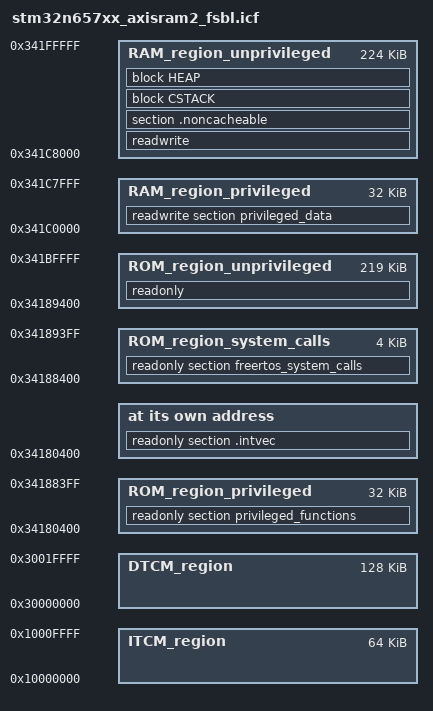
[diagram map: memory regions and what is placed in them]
/*###ICF### Section handled by ICF editor, don't touch! ****/
/*-Editor annotation file-*/
/* IcfEditorFile="$TOOLKIT_DIR$\config\ide\IcfEditor\cortex_v1_0.xml" */
/*-Specials-*/
define symbol __ICFEDIT_intvec_start__ = 0x34180400;
/*-Memory Regions-*/
define symbol __ICFEDIT_region_ROM_start__ = 0x34180400;
define symbol __ICFEDIT_region_ROM_end__   = 0x341BFFFF;
define symbol __ICFEDIT_region_RAM_start__ = 0x341C0000;
define symbol __ICFEDIT_region_RAM_end__   = 0x341FFFFF;
/*-Sizes-*/
define symbol __ICFEDIT_size_cstack__ = 0x800;
define symbol __ICFEDIT_size_heap__   = 0x200;
/**** End of ICF editor section. ###ICF###*/

define symbol __region_ITCM_start__  = 0x10000000;
define symbol __region_ITCM_end__    = 0x1000FFFF;
define symbol __region_DTCM_start__  = 0x30000000;
define symbol __region_DTCM_end__    = 0x3001FFFF;


/* Flash Organization
 *  1. Privileged Code:
 *      Start   : 0x34180400
 *      End     : 0x341883FF
 *      Size    : 32 Kbytes
 *  2. System calls:
 *      Start   : 0x34188400
 *      End     : 0x341893FF
 *      Size    : 4 Kbytes
 *  3. Unprivileged Code:
 *      Start   : 0x34189400
 *      End     : 0x341BFFFF
 *      Size    : 549 Kbytes
 */
define symbol __reigon_ROM_privileged_start__   = __ICFEDIT_region_ROM_start__;
define symbol __reigon_ROM_privileged_end__     = 0x341883FF;
define symbol __reigon_ROM_system_calls_start__ = 0x34188400;
define symbol __reigon_ROM_system_calls_end__   = 0x341893FF;
define symbol __reigon_ROM_unprivileged_start__ = 0x34189400;
define symbol __reigon_ROM_unprivileged_end__   = __ICFEDIT_region_ROM_end__;

/* RAM Organization [Total RAM Size = 640 Kbytes]
 *  1. Privileged Data:
 *      Start   : 0x341C0000
 *      End     : 0x341C7FFF
 *      Size    : 32 Kbytes
 *  2. Unprivileged Data:
 *      Start   : 0x341C8000
 *      End     : 0x341FFFFF
 *      Size    : 224 Kbytes
 */
define symbol __region_RAM_privileged_start__   = __ICFEDIT_region_RAM_start__;
define symbol __region_RAM_privileged_end__     = 0x341C7FFF;
define symbol __region_RAM_unprivileged_start__ = 0x341C8000;
define symbol __region_RAM_unprivileged_end__   = __ICFEDIT_region_RAM_end__;
define memory mem with size = 4G;
define region ROM_region_privileged     = mem:[from __reigon_ROM_privileged_start__ to __reigon_ROM_privileged_end__];
define region ROM_region_system_calls   = mem:[from __reigon_ROM_system_calls_start__ to __reigon_ROM_system_calls_end__];
define region ROM_region_unprivileged   = mem:[from __reigon_ROM_unprivileged_start__ to __reigon_ROM_unprivileged_end__];
define region RAM_region_privileged     = mem:[from __region_RAM_privileged_start__   to __region_RAM_privileged_end__];
define region RAM_region_unprivileged   = mem:[from __region_RAM_unprivileged_start__   to __region_RAM_unprivileged_end__];
define region ITCM_region     = mem:[from __region_ITCM_start__ to __region_ITCM_end__];
define region DTCM_region     = mem:[from __region_DTCM_start__ to __region_DTCM_end__];

define block CSTACK    with alignment = 8, size = __ICFEDIT_size_cstack__   { };
define block HEAP      with alignment = 8, size = __ICFEDIT_size_heap__     { };

initialize by copy { readwrite };
do not initialize  { section .noinit };

/* Exported symbols. */
define exported symbol __unprivileged_flash_start__          = __reigon_ROM_unprivileged_start__;
define exported symbol __unprivileged_flash_end__            = __reigon_ROM_unprivileged_end__;
define exported symbol __SRAM_segment_start__           = __ICFEDIT_region_RAM_start__;
define exported symbol __SRAM_segment_end__             = __ICFEDIT_region_RAM_end__;

define exported symbol __privileged_functions_start__   = __reigon_ROM_privileged_start__;
define exported symbol __privileged_functions_end__     = __reigon_ROM_privileged_end__;
define exported symbol __privileged_sram_start__        = __region_RAM_privileged_start__;
define exported symbol __privileged_sram_end__          = __region_RAM_privileged_end__;

define exported symbol __syscalls_flash_start__         = __reigon_ROM_system_calls_start__;
define exported symbol __syscalls_flash_end__           = __reigon_ROM_system_calls_end__;
place at address mem:__ICFEDIT_intvec_start__ { readonly section .intvec };

place in ROM_region_privileged      { readonly section privileged_functions };
place in ROM_region_system_calls    { readonly section freertos_system_calls };
place in ROM_region_unprivileged    { readonly };

place in RAM_region_privileged      { readwrite section privileged_data };
place in RAM_region_unprivileged    { readwrite, section .noncacheable,
                                      block CSTACK, block HEAP };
